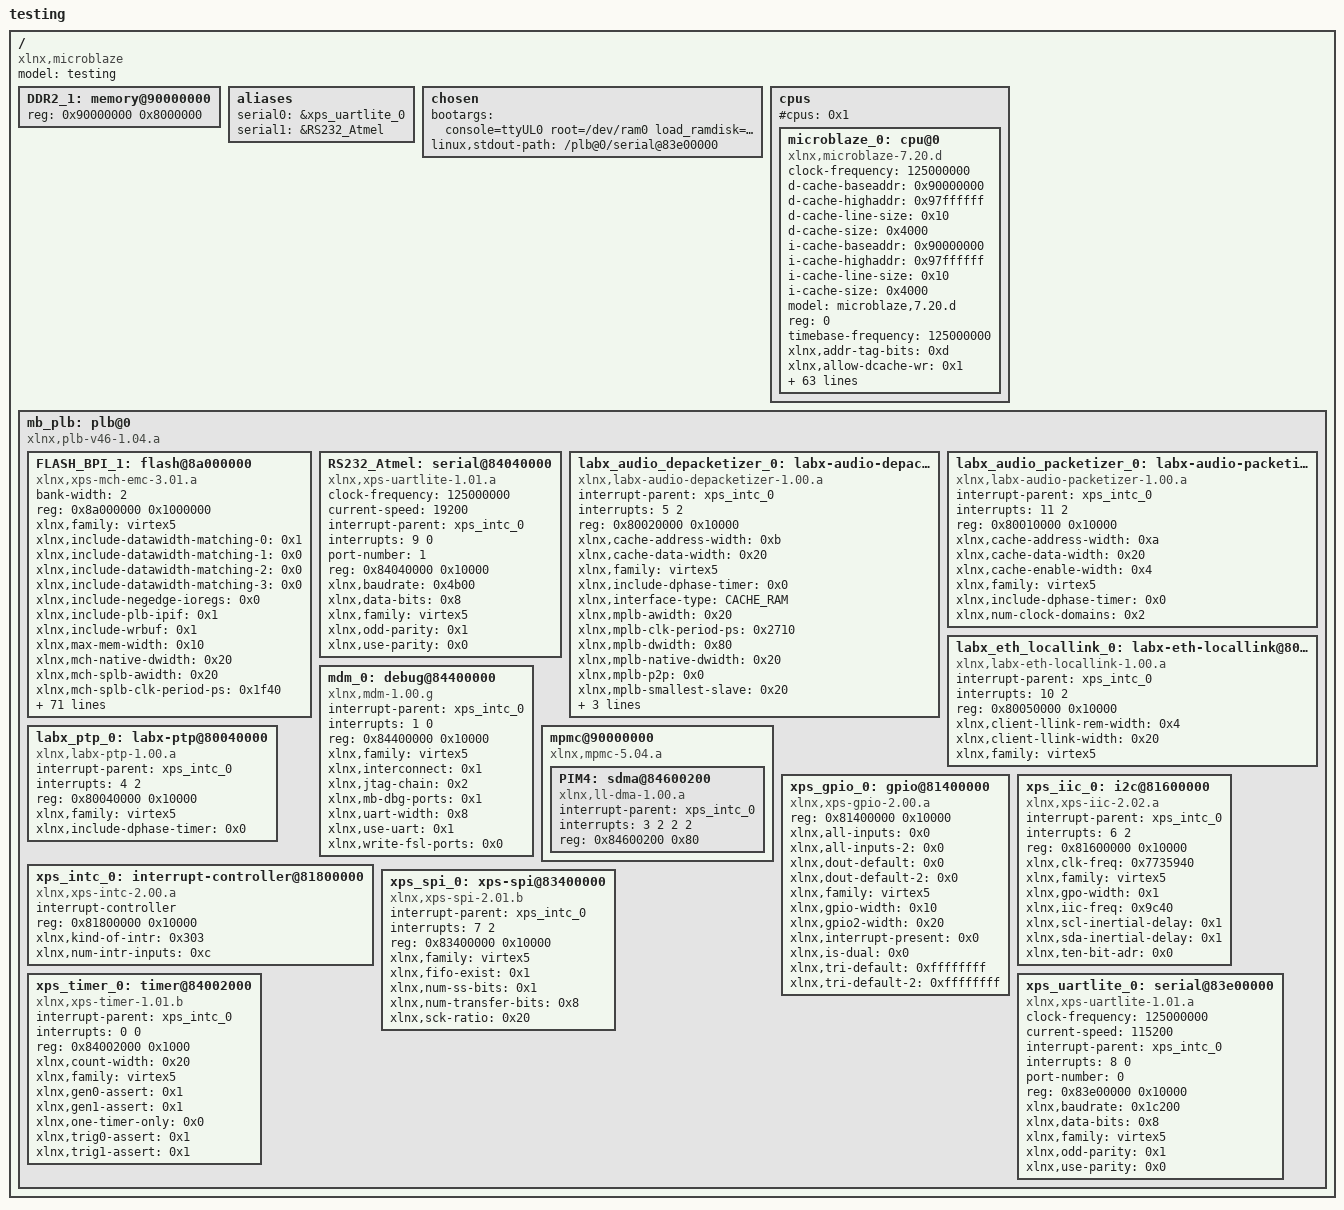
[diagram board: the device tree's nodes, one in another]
/*
 * Device Tree Generator version: 1.3
 *
 * (C) Copyright 2007-2008 Xilinx, Inc.
 * (C) Copyright 2007-2009 Michal Simek
 *
 * Michal SIMEK <monstr@monstr.eu>
 *
 * This program is free software; you can redistribute it and/or
 * modify it under the terms of the GNU General Public License as
 * published by the Free Software Foundation; either version 2 of
 * the License, or (at your option) any later version.
 *
 * This program is distributed in the hope that it will be useful,
 * but WITHOUT ANY WARRANTY; without even the implied warranty of
 * MERCHANTABILITY or FITNESS FOR A PARTICULAR PURPOSE. See the
 * GNU General Public License for more details.
 *
 * You should have received a copy of the GNU General Public License
 * along with this program; if not, write to the Free Software
 * Foundation, Inc., 59 Temple Place, Suite 330, Boston,
 * MA 02111-1307 USA
 *
 * CAUTION: This file is automatically generated by libgen.
 * Version: Xilinx EDK 11.4 EDK_LS4.68
 *
 * XPS project directory: micro
 */

/dts-v1/;
/ {
	#address-cells = <1>;
	#size-cells = <1>;
	compatible = "xlnx,microblaze";
	model = "testing";
	DDR2_1: memory@90000000 {
		device_type = "memory";
		reg = < 0x90000000 0x8000000 >;
	} ;
	aliases {
		serial0 = &xps_uartlite_0;
		serial1 = &RS232_Atmel;
	} ;
	chosen {
		bootargs = "console=ttyUL0 root=/dev/ram0 load_ramdisk=1 ramdisk_start=4096 prompt_ramdisk=0 BUTTONS=0x00";
		linux,stdout-path = "/plb@0/serial@83e00000";
	} ;
	cpus {
		#address-cells = <1>;
		#cpus = <0x1>;
		#size-cells = <0>;
		microblaze_0: cpu@0 {
			clock-frequency = <125000000>;
			compatible = "xlnx,microblaze-7.20.d";
			d-cache-baseaddr = <0x90000000>;
			d-cache-highaddr = <0x97ffffff>;
			d-cache-line-size = <0x10>;
			d-cache-size = <0x4000>;
			device_type = "cpu";
			i-cache-baseaddr = <0x90000000>;
			i-cache-highaddr = <0x97ffffff>;
			i-cache-line-size = <0x10>;
			i-cache-size = <0x4000>;
			model = "microblaze,7.20.d";
			reg = <0>;
			timebase-frequency = <125000000>;
			xlnx,addr-tag-bits = <0xd>;
			xlnx,allow-dcache-wr = <0x1>;
			xlnx,allow-icache-wr = <0x1>;
			xlnx,area-optimized = <0x0>;
			xlnx,cache-byte-size = <0x4000>;
			xlnx,d-lmb = <0x1>;
			xlnx,d-opb = <0x0>;
			xlnx,d-plb = <0x1>;
			xlnx,data-size = <0x20>;
			xlnx,dcache-addr-tag = <0xd>;
			xlnx,dcache-always-used = <0x1>;
			xlnx,dcache-byte-size = <0x4000>;
			xlnx,dcache-interface = <0x0>;
			xlnx,dcache-line-len = <0x4>;
			xlnx,dcache-use-fsl = <0x1>;
			xlnx,dcache-use-writeback = <0x0>;
			xlnx,debug-enabled = <0x1>;
			xlnx,div-zero-exception = <0x1>;
			xlnx,dopb-bus-exception = <0x0>;
			xlnx,dynamic-bus-sizing = <0x1>;
			xlnx,edge-is-positive = <0x1>;
			xlnx,family = "virtex5";
			xlnx,fpu-exception = <0x1>;
			xlnx,fsl-data-size = <0x20>;
			xlnx,fsl-exception = <0x0>;
			xlnx,fsl-links = <0x0>;
			xlnx,i-lmb = <0x1>;
			xlnx,i-opb = <0x0>;
			xlnx,i-plb = <0x1>;
			xlnx,icache-always-used = <0x1>;
			xlnx,icache-interface = <0x0>;
			xlnx,icache-line-len = <0x4>;
			xlnx,icache-use-fsl = <0x1>;
			xlnx,ill-opcode-exception = <0x1>;
			xlnx,instance = "microblaze_0";
			xlnx,interconnect = <0x1>;
			xlnx,interrupt-is-edge = <0x0>;
			xlnx,iopb-bus-exception = <0x0>;
			xlnx,mmu-dtlb-size = <0x4>;
			xlnx,mmu-itlb-size = <0x2>;
			xlnx,mmu-tlb-access = <0x3>;
			xlnx,mmu-zones = <0x10>;
			xlnx,number-of-pc-brk = <0x1>;
			xlnx,number-of-rd-addr-brk = <0x0>;
			xlnx,number-of-wr-addr-brk = <0x0>;
			xlnx,opcode-0x0-illegal = <0x1>;
			xlnx,pvr = <0x2>;
			xlnx,pvr-user1 = <0x0>;
			xlnx,pvr-user2 = <0x0>;
			xlnx,reset-msr = <0x0>;
			xlnx,sco = <0x0>;
			xlnx,unaligned-exceptions = <0x1>;
			xlnx,use-barrel = <0x1>;
			xlnx,use-dcache = <0x1>;
			xlnx,use-div = <0x1>;
			xlnx,use-ext-brk = <0x1>;
			xlnx,use-ext-nm-brk = <0x1>;
			xlnx,use-extended-fsl-instr = <0x0>;
			xlnx,use-fpu = <0x2>;
			xlnx,use-hw-mul = <0x2>;
			xlnx,use-icache = <0x1>;
			xlnx,use-interrupt = <0x1>;
			xlnx,use-mmu = <0x3>;
			xlnx,use-msr-instr = <0x1>;
			xlnx,use-pcmp-instr = <0x1>;
		} ;
	} ;
	mb_plb: plb@0 {
		#address-cells = <1>;
		#size-cells = <1>;
		compatible = "xlnx,plb-v46-1.04.a", "xlnx,plb-v46-1.00.a", "simple-bus";
		ranges ;
		FLASH_BPI_1: flash@8a000000 {
			bank-width = <2>;
			compatible = "xlnx,xps-mch-emc-3.01.a", "cfi-flash";
			reg = < 0x8a000000 0x1000000 >;
			xlnx,family = "virtex5";
			xlnx,include-datawidth-matching-0 = <0x1>;
			xlnx,include-datawidth-matching-1 = <0x0>;
			xlnx,include-datawidth-matching-2 = <0x0>;
			xlnx,include-datawidth-matching-3 = <0x0>;
			xlnx,include-negedge-ioregs = <0x0>;
			xlnx,include-plb-ipif = <0x1>;
			xlnx,include-wrbuf = <0x1>;
			xlnx,max-mem-width = <0x10>;
			xlnx,mch-native-dwidth = <0x20>;
			xlnx,mch-splb-awidth = <0x20>;
			xlnx,mch-splb-clk-period-ps = <0x1f40>;
			xlnx,mch0-accessbuf-depth = <0x10>;
			xlnx,mch0-protocol = <0x0>;
			xlnx,mch0-rddatabuf-depth = <0x10>;
			xlnx,mch1-accessbuf-depth = <0x10>;
			xlnx,mch1-protocol = <0x0>;
			xlnx,mch1-rddatabuf-depth = <0x10>;
			xlnx,mch2-accessbuf-depth = <0x10>;
			xlnx,mch2-protocol = <0x0>;
			xlnx,mch2-rddatabuf-depth = <0x10>;
			xlnx,mch3-accessbuf-depth = <0x10>;
			xlnx,mch3-protocol = <0x0>;
			xlnx,mch3-rddatabuf-depth = <0x10>;
			xlnx,mem0-width = <0x10>;
			xlnx,mem1-width = <0x20>;
			xlnx,mem2-width = <0x20>;
			xlnx,mem3-width = <0x20>;
			xlnx,num-banks-mem = <0x1>;
			xlnx,num-channels = <0x0>;
			xlnx,pagemode-flash-0 = <0x0>;
			xlnx,pagemode-flash-1 = <0x0>;
			xlnx,pagemode-flash-2 = <0x0>;
			xlnx,pagemode-flash-3 = <0x0>;
			xlnx,priority-mode = <0x0>;
			xlnx,synch-mem-0 = <0x0>;
			xlnx,synch-mem-1 = <0x0>;
			xlnx,synch-mem-2 = <0x0>;
			xlnx,synch-mem-3 = <0x0>;
			xlnx,synch-pipedelay-0 = <0x2>;
			xlnx,synch-pipedelay-1 = <0x2>;
			xlnx,synch-pipedelay-2 = <0x2>;
			xlnx,synch-pipedelay-3 = <0x2>;
			xlnx,tavdv-ps-mem-0 = <0x14c08>;
			xlnx,tavdv-ps-mem-1 = <0x3a98>;
			xlnx,tavdv-ps-mem-2 = <0x3a98>;
			xlnx,tavdv-ps-mem-3 = <0x3a98>;
			xlnx,tcedv-ps-mem-0 = <0x14c08>;
			xlnx,tcedv-ps-mem-1 = <0x3a98>;
			xlnx,tcedv-ps-mem-2 = <0x3a98>;
			xlnx,tcedv-ps-mem-3 = <0x3a98>;
			xlnx,thzce-ps-mem-0 = <0x5dc0>;
			xlnx,thzce-ps-mem-1 = <0x1b58>;
			xlnx,thzce-ps-mem-2 = <0x1b58>;
			xlnx,thzce-ps-mem-3 = <0x1b58>;
			xlnx,thzoe-ps-mem-0 = <0x5dc0>;
			xlnx,thzoe-ps-mem-1 = <0x1b58>;
			xlnx,thzoe-ps-mem-2 = <0x1b58>;
			xlnx,thzoe-ps-mem-3 = <0x1b58>;
			xlnx,tlzwe-ps-mem-0 = <0x0>;
			xlnx,tlzwe-ps-mem-1 = <0x0>;
			xlnx,tlzwe-ps-mem-2 = <0x0>;
			xlnx,tlzwe-ps-mem-3 = <0x0>;
			xlnx,tpacc-ps-flash-0 = <0x61a8>;
			xlnx,tpacc-ps-flash-1 = <0x61a8>;
			xlnx,tpacc-ps-flash-2 = <0x61a8>;
			xlnx,tpacc-ps-flash-3 = <0x61a8>;
			xlnx,twc-ps-mem-0 = <0x11170>;
			xlnx,twc-ps-mem-1 = <0x3a98>;
			xlnx,twc-ps-mem-2 = <0x3a98>;
			xlnx,twc-ps-mem-3 = <0x3a98>;
			xlnx,twp-ps-mem-0 = <0xc350>;
			xlnx,twp-ps-mem-1 = <0x2ee0>;
			xlnx,twp-ps-mem-2 = <0x2ee0>;
			xlnx,twp-ps-mem-3 = <0x2ee0>;
			xlnx,xcl0-linesize = <0x4>;
			xlnx,xcl0-writexfer = <0x1>;
			xlnx,xcl1-linesize = <0x4>;
			xlnx,xcl1-writexfer = <0x1>;
			xlnx,xcl2-linesize = <0x4>;
			xlnx,xcl2-writexfer = <0x1>;
			xlnx,xcl3-linesize = <0x4>;
			xlnx,xcl3-writexfer = <0x1>;
		} ;
		RS232_Atmel: serial@84040000 {
			clock-frequency = <125000000>;
			compatible = "xlnx,xps-uartlite-1.01.a", "xlnx,xps-uartlite-1.00.a";
			current-speed = <19200>;
			device_type = "serial";
			interrupt-parent = <&xps_intc_0>;
			interrupts = < 9 0 >;
			port-number = <1>;
			reg = < 0x84040000 0x10000 >;
			xlnx,baudrate = <0x4b00>;
			xlnx,data-bits = <0x8>;
			xlnx,family = "virtex5";
			xlnx,odd-parity = <0x1>;
			xlnx,use-parity = <0x0>;
		} ;
		labx_audio_depacketizer_0: labx-audio-depacketizer@80020000 {
			compatible = "xlnx,labx-audio-depacketizer-1.00.a";
			interrupt-parent = <&xps_intc_0>;
			interrupts = < 5 2 >;
			reg = < 0x80020000 0x10000 >;
			xlnx,cache-address-width = <0xb>;
			xlnx,cache-data-width = <0x20>;
			xlnx,family = "virtex5";
			xlnx,include-dphase-timer = <0x0>;
			xlnx,interface-type = "CACHE_RAM";
			xlnx,mplb-awidth = <0x20>;
			xlnx,mplb-clk-period-ps = <0x2710>;
			xlnx,mplb-dwidth = <0x80>;
			xlnx,mplb-native-dwidth = <0x20>;
			xlnx,mplb-p2p = <0x0>;
			xlnx,mplb-smallest-slave = <0x20>;
			xlnx,npi-data-width = <0x20>;
			xlnx,num-clock-domains = <0x2>;
			xlnx,param-address-width = <0xa>;
		} ;
		labx_audio_packetizer_0: labx-audio-packetizer@80010000 {
			compatible = "xlnx,labx-audio-packetizer-1.00.a";
			interrupt-parent = <&xps_intc_0>;
			interrupts = < 11 2 >;
			reg = < 0x80010000 0x10000 >;
			xlnx,cache-address-width = <0xa>;
			xlnx,cache-data-width = <0x20>;
			xlnx,cache-enable-width = <0x4>;
			xlnx,family = "virtex5";
			xlnx,include-dphase-timer = <0x0>;
			xlnx,num-clock-domains = <0x2>;
		} ;
		labx_eth_locallink_0: labx-eth-locallink@80050000 {
			compatible = "xlnx,labx-eth-locallink-1.00.a";
			interrupt-parent = <&xps_intc_0>;
			interrupts = < 10 2 >;
			reg = < 0x80050000 0x10000 >;
			xlnx,client-llink-rem-width = <0x4>;
			xlnx,client-llink-width = <0x20>;
			xlnx,family = "virtex5";
		} ;
		labx_ptp_0: labx-ptp@80040000 {
			compatible = "xlnx,labx-ptp-1.00.a";
			interrupt-parent = <&xps_intc_0>;
			interrupts = < 4 2 >;
			reg = < 0x80040000 0x10000 >;
			xlnx,family = "virtex5";
			xlnx,include-dphase-timer = <0x0>;
		} ;
		mdm_0: debug@84400000 {
			compatible = "xlnx,mdm-1.00.g";
			interrupt-parent = <&xps_intc_0>;
			interrupts = < 1 0 >;
			reg = < 0x84400000 0x10000 >;
			xlnx,family = "virtex5";
			xlnx,interconnect = <0x1>;
			xlnx,jtag-chain = <0x2>;
			xlnx,mb-dbg-ports = <0x1>;
			xlnx,uart-width = <0x8>;
			xlnx,use-uart = <0x1>;
			xlnx,write-fsl-ports = <0x0>;
		} ;
		mpmc@90000000 {
			#address-cells = <1>;
			#size-cells = <1>;
			compatible = "xlnx,mpmc-5.04.a";
			PIM4: sdma@84600200 {
				compatible = "xlnx,ll-dma-1.00.a";
				interrupt-parent = <&xps_intc_0>;
				interrupts = < 3 2 2 2 >;
				reg = < 0x84600200 0x80 >;
			} ;
		} ;
		xps_gpio_0: gpio@81400000 {
			compatible = "xlnx,xps-gpio-2.00.a", "xlnx,xps-gpio-1.00.a";
			reg = < 0x81400000 0x10000 >;
			xlnx,all-inputs = <0x0>;
			xlnx,all-inputs-2 = <0x0>;
			xlnx,dout-default = <0x0>;
			xlnx,dout-default-2 = <0x0>;
			xlnx,family = "virtex5";
			xlnx,gpio-width = <0x10>;
			xlnx,gpio2-width = <0x20>;
			xlnx,interrupt-present = <0x0>;
			xlnx,is-dual = <0x0>;
			xlnx,tri-default = <0xffffffff>;
			xlnx,tri-default-2 = <0xffffffff>;
		} ;
		xps_iic_0: i2c@81600000 {
			compatible = "xlnx,xps-iic-2.02.a", "xlnx,xps-iic-2.00.a";
			interrupt-parent = <&xps_intc_0>;
			interrupts = < 6 2 >;
			reg = < 0x81600000 0x10000 >;
			xlnx,clk-freq = <0x7735940>;
			xlnx,family = "virtex5";
			xlnx,gpo-width = <0x1>;
			xlnx,iic-freq = <0x9c40>;
			xlnx,scl-inertial-delay = <0x1>;
			xlnx,sda-inertial-delay = <0x1>;
			xlnx,ten-bit-adr = <0x0>;
		} ;
		xps_intc_0: interrupt-controller@81800000 {
			#interrupt-cells = <0x2>;
			compatible = "xlnx,xps-intc-2.00.a", "xlnx,xps-intc-1.00.a";
			interrupt-controller ;
			reg = < 0x81800000 0x10000 >;
			xlnx,kind-of-intr = <0x303>;
			xlnx,num-intr-inputs = <0xc>;
		} ;
		xps_spi_0: xps-spi@83400000 {
			compatible = "xlnx,xps-spi-2.01.b", "xlnx,xps-spi-2.00.a";
			interrupt-parent = <&xps_intc_0>;
			interrupts = < 7 2 >;
			reg = < 0x83400000 0x10000 >;
			xlnx,family = "virtex5";
			xlnx,fifo-exist = <0x1>;
			xlnx,num-ss-bits = <0x1>;
			xlnx,num-transfer-bits = <0x8>;
			xlnx,sck-ratio = <0x20>;
		} ;
		xps_timer_0: timer@84002000 {
			compatible = "xlnx,xps-timer-1.01.b", "xlnx,xps-timer-1.00.a";
			interrupt-parent = <&xps_intc_0>;
			interrupts = < 0 0 >;
			reg = < 0x84002000 0x1000 >;
			xlnx,count-width = <0x20>;
			xlnx,family = "virtex5";
			xlnx,gen0-assert = <0x1>;
			xlnx,gen1-assert = <0x1>;
			xlnx,one-timer-only = <0x0>;
			xlnx,trig0-assert = <0x1>;
			xlnx,trig1-assert = <0x1>;
		} ;
		xps_uartlite_0: serial@83e00000 {
			clock-frequency = <125000000>;
			compatible = "xlnx,xps-uartlite-1.01.a", "xlnx,xps-uartlite-1.00.a";
			current-speed = <115200>;
			device_type = "serial";
			interrupt-parent = <&xps_intc_0>;
			interrupts = < 8 0 >;
			port-number = <0>;
			reg = < 0x83e00000 0x10000 >;
			xlnx,baudrate = <0x1c200>;
			xlnx,data-bits = <0x8>;
			xlnx,family = "virtex5";
			xlnx,odd-parity = <0x1>;
			xlnx,use-parity = <0x0>;
		} ;
	} ;
}  ;
